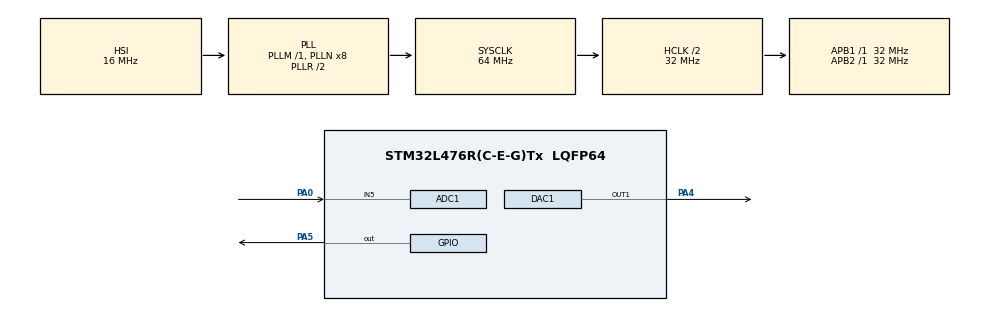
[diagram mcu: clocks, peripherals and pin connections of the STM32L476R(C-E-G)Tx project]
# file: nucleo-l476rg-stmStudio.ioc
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ADC1.Channel-2\#ChannelRegularConversion=ADC_CHANNEL_5
ADC1.ClockPrescaler=ADC_CLOCK_SYNC_PCLK_DIV2
ADC1.ContinuousConvMode=ENABLE
ADC1.NbrOfConversionFlag=1
ADC1.OffsetNumber-2\#ChannelRegularConversion=ADC_OFFSET_NONE
ADC1.Rank-2\#ChannelRegularConversion=1
ADC1.SamplingTime-2\#ChannelRegularConversion=ADC_SAMPLETIME_47CYCLES_5
ADC1.master=1
Mcu.Family=STM32L4
Mcu.Name=STM32L476R(C-E-G)Tx
Mcu.Package=LQFP64
NVIC.PriorityGroup=NVIC_PRIORITYGROUP_4
PA0.Signal=ADCx_IN5
PA13\ (JTMS-SWDIO).Mode=Serial_Wire
PA13\ (JTMS-SWDIO).Signal=SYS_JTMS-SWDIO
PA14\ (JTCK-SWCLK).Mode=Serial_Wire
PA14\ (JTCK-SWCLK).Signal=SYS_JTCK-SWCLK
PA4.Signal=COMP_DAC11_group
PA5.Signal=GPIO_Output
ProjectManager.HeapSize=0x200
ProjectManager.StackSize=0x400
ProjectManager.TargetToolchain=STM32CubeIDE
RCC.ADCFreq_Value=64000000
RCC.AHBCLKDivider=RCC_SYSCLK_DIV2
RCC.AHBFreq_Value=32000000
RCC.APB1Freq_Value=32000000
RCC.APB1TimFreq_Value=32000000
RCC.APB2Freq_Value=32000000
RCC.APB2TimFreq_Value=32000000
RCC.CortexFreq_Value=32000000
RCC.HCLKFreq_Value=32000000
RCC.HSE_VALUE=8000000
RCC.HSI_VALUE=16000000
RCC.MSI_VALUE=4000000
RCC.PLLSourceVirtual=RCC_PLLSOURCE_HSI
RCC.PREFETCH_ENABLE=1
RCC.SYSCLKFreq_VALUE=64000000
RCC.SYSCLKSource=RCC_SYSCLKSOURCE_PLLCLK
RCC.USBFreq_Value=64000000
RCC.VCOOutputFreq_Value=128000000
SH.ADCx_IN5.0=ADC1_IN5,IN5-Single-Ended
SH.COMP_DAC11_group.0=DAC1_OUT1,DAC_OUT1
board=NUCLEO-L476RG

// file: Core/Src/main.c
/* USER CODE BEGIN Header */
/**
  ******************************************************************************
  * @file           : main.c
  * @brief          : Main program body
  ******************************************************************************
  * @attention
  *
  * Copyright (c) 2023 STMicroelectronics.
  * All rights reserved.
  *
  * This software is licensed under terms that can be found in the LICENSE file
  * in the root directory of this software component.
  * If no LICENSE file comes with this software, it is provided AS-IS.
  *
  ******************************************************************************
  */
/* USER CODE END Header */
#include "main.h"

ADC_HandleTypeDef hadc1;

DAC_HandleTypeDef hdac1;

/* USER CODE BEGIN PV */
uint32_t value_adc;
uint32_t value_dac;

/* USER CODE END PV */

void SystemClock_Config(void);
static void MX_GPIO_Init(void);
static void MX_ADC1_Init(void);
static void MX_DAC1_Init(void);

int main(void)
{

  /* MCU Configuration--------------------------------------------------------*/

  /* Reset of all peripherals, Initializes the Flash interface and the Systick. */
  HAL_Init();

  /* Configure the system clock */
  SystemClock_Config();

  /* Initialize all configured peripherals */
  MX_GPIO_Init();
  MX_ADC1_Init();
  MX_DAC1_Init();

  /* USER CODE BEGIN 2 */
  if (HAL_ADCEx_Calibration_Start(&hadc1, ADC_SINGLE_ENDED) != HAL_OK)
  {
	Error_Handler();
  }
  HAL_DAC_Start(&hdac1, DAC_CHANNEL_1);
  HAL_DAC_SetValue(&hdac1, DAC_CHANNEL_1, DAC_ALIGN_12B_L, value_dac);
  if (HAL_ADC_Start(&hadc1) != HAL_OK)
  {
	  Error_Handler();
  }

  /* USER CODE END 2 */

  /* Infinite loop */
  while (1)
  {

    /* USER CODE BEGIN 3 */
	  HAL_ADC_PollForConversion(&hadc1, 5);
	  // Check if the conversion is finished
	  if ((HAL_ADC_GetState(&hadc1) & HAL_ADC_STATE_REG_EOC) == HAL_ADC_STATE_REG_EOC)
	  {
		  value_adc = HAL_ADC_GetValue(&hadc1);
	  }
	  HAL_DAC_SetValue(&hdac1, DAC_CHANNEL_1, DAC_ALIGN_12B_L, value_dac);
	  value_dac++;
	  if (value_dac > 4095)
	  {
		  value_dac = 0;
	  }
	  HAL_GPIO_TogglePin(GPIOA, GPIO_PIN_5);
	  HAL_Delay(1);
  }
  /* USER CODE END 3 */
}

void SystemClock_Config(void)
{
  RCC_OscInitTypeDef RCC_OscInitStruct = {0};
  RCC_ClkInitTypeDef RCC_ClkInitStruct = {0};

  /** Configure the main internal regulator output voltage
  */
  if (HAL_PWREx_ControlVoltageScaling(PWR_REGULATOR_VOLTAGE_SCALE1) != HAL_OK)
  {
    Error_Handler();
  }

  /** Initializes the RCC Oscillators according to the specified parameters
  * in the RCC_OscInitTypeDef structure.
  */
  RCC_OscInitStruct.OscillatorType = RCC_OSCILLATORTYPE_HSI;
  RCC_OscInitStruct.HSIState = RCC_HSI_ON;
  RCC_OscInitStruct.HSICalibrationValue = RCC_HSICALIBRATION_DEFAULT;
  RCC_OscInitStruct.PLL.PLLState = RCC_PLL_ON;
  RCC_OscInitStruct.PLL.PLLSource = RCC_PLLSOURCE_HSI;
  RCC_OscInitStruct.PLL.PLLM = 1;
  RCC_OscInitStruct.PLL.PLLN = 8;
  RCC_OscInitStruct.PLL.PLLP = RCC_PLLP_DIV7;
  RCC_OscInitStruct.PLL.PLLQ = RCC_PLLQ_DIV2;
  RCC_OscInitStruct.PLL.PLLR = RCC_PLLR_DIV2;
  if (HAL_RCC_OscConfig(&RCC_OscInitStruct) != HAL_OK)
  {
    Error_Handler();
  }

  /** Initializes the CPU, AHB and APB buses clocks
  */
  RCC_ClkInitStruct.ClockType = RCC_CLOCKTYPE_HCLK|RCC_CLOCKTYPE_SYSCLK
                              |RCC_CLOCKTYPE_PCLK1|RCC_CLOCKTYPE_PCLK2;
  RCC_ClkInitStruct.SYSCLKSource = RCC_SYSCLKSOURCE_PLLCLK;
  RCC_ClkInitStruct.AHBCLKDivider = RCC_SYSCLK_DIV2;
  RCC_ClkInitStruct.APB1CLKDivider = RCC_HCLK_DIV1;
  RCC_ClkInitStruct.APB2CLKDivider = RCC_HCLK_DIV1;

  if (HAL_RCC_ClockConfig(&RCC_ClkInitStruct, FLASH_LATENCY_1) != HAL_OK)
  {
    Error_Handler();
  }
}

static void MX_ADC1_Init(void)
{

  ADC_MultiModeTypeDef multimode = {0};
  ADC_ChannelConfTypeDef sConfig = {0};

  /** Common config
  */
  hadc1.Instance = ADC1;
  hadc1.Init.ClockPrescaler = ADC_CLOCK_SYNC_PCLK_DIV2;
  hadc1.Init.Resolution = ADC_RESOLUTION_12B;
  hadc1.Init.DataAlign = ADC_DATAALIGN_RIGHT;
  hadc1.Init.ScanConvMode = ADC_SCAN_DISABLE;
  hadc1.Init.EOCSelection = ADC_EOC_SINGLE_CONV;
  hadc1.Init.LowPowerAutoWait = DISABLE;
  hadc1.Init.ContinuousConvMode = ENABLE;
  hadc1.Init.NbrOfConversion = 1;
  hadc1.Init.DiscontinuousConvMode = DISABLE;
  hadc1.Init.ExternalTrigConv = ADC_SOFTWARE_START;
  hadc1.Init.ExternalTrigConvEdge = ADC_EXTERNALTRIGCONVEDGE_NONE;
  hadc1.Init.DMAContinuousRequests = DISABLE;
  hadc1.Init.Overrun = ADC_OVR_DATA_PRESERVED;
  hadc1.Init.OversamplingMode = DISABLE;
  if (HAL_ADC_Init(&hadc1) != HAL_OK)
  {
    Error_Handler();
  }

  /** Configure the ADC multi-mode
  */
  multimode.Mode = ADC_MODE_INDEPENDENT;
  if (HAL_ADCEx_MultiModeConfigChannel(&hadc1, &multimode) != HAL_OK)
  {
    Error_Handler();
  }

  /** Configure Regular Channel
  */
  sConfig.Channel = ADC_CHANNEL_5;
  sConfig.Rank = ADC_REGULAR_RANK_1;
  sConfig.SamplingTime = ADC_SAMPLETIME_47CYCLES_5;
  sConfig.SingleDiff = ADC_SINGLE_ENDED;
  sConfig.OffsetNumber = ADC_OFFSET_NONE;
  sConfig.Offset = 0;
  if (HAL_ADC_ConfigChannel(&hadc1, &sConfig) != HAL_OK)
  {
    Error_Handler();
  }

}

static void MX_DAC1_Init(void)
{

  DAC_ChannelConfTypeDef sConfig = {0};

  /** DAC Initialization
  */
  hdac1.Instance = DAC1;
  if (HAL_DAC_Init(&hdac1) != HAL_OK)
  {
    Error_Handler();
  }

  /** DAC channel OUT1 config
  */
  sConfig.DAC_SampleAndHold = DAC_SAMPLEANDHOLD_DISABLE;
  sConfig.DAC_Trigger = DAC_TRIGGER_NONE;
  sConfig.DAC_OutputBuffer = DAC_OUTPUTBUFFER_ENABLE;
  sConfig.DAC_ConnectOnChipPeripheral = DAC_CHIPCONNECT_DISABLE;
  sConfig.DAC_UserTrimming = DAC_TRIMMING_FACTORY;
  if (HAL_DAC_ConfigChannel(&hdac1, &sConfig, DAC_CHANNEL_1) != HAL_OK)
  {
    Error_Handler();
  }

}

static void MX_GPIO_Init(void)
{
  GPIO_InitTypeDef GPIO_InitStruct = {0};

  /* GPIO Ports Clock Enable */
  __HAL_RCC_GPIOA_CLK_ENABLE();

  /*Configure GPIO pin Output Level */
  HAL_GPIO_WritePin(GPIOA, GPIO_PIN_5, GPIO_PIN_RESET);

  /*Configure GPIO pin : PA5 */
  GPIO_InitStruct.Pin = GPIO_PIN_5;
  GPIO_InitStruct.Mode = GPIO_MODE_OUTPUT_PP;
  GPIO_InitStruct.Pull = GPIO_NOPULL;
  GPIO_InitStruct.Speed = GPIO_SPEED_FREQ_LOW;
  HAL_GPIO_Init(GPIOA, &GPIO_InitStruct);

}

void Error_Handler(void)
{
  __disable_irq();
  while (1)
  {
  }
}
